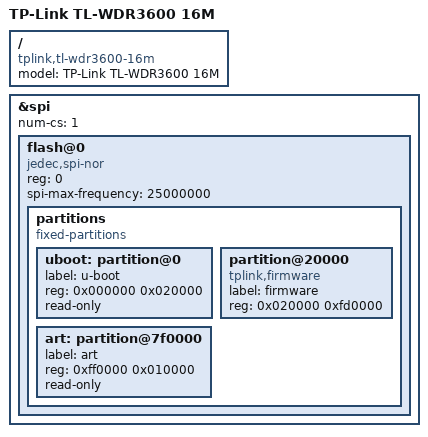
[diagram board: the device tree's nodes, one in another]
// SPDX-License-Identifier: GPL-2.0-or-later OR MIT
/dts-v1/;

#include "ar9344_tplink_tl-wdr4300.dtsi"

/ {
	model = "TP-Link TL-WDR3600 16M";
	compatible = "tplink,tl-wdr3600-16m", "qca,ar9344";
};

&spi {
       num-cs = <1>;

       status = "okay";

       flash@0 {
               compatible = "jedec,spi-nor";
               reg = <0>;
               spi-max-frequency = <25000000>;

               partitions {
                       compatible = "fixed-partitions";
                       #address-cells = <1>;
                       #size-cells = <1>;

                       uboot: partition@0 {
                               label = "u-boot";
                               reg = <0x000000 0x020000>;
                               read-only;
                       };

                       partition@20000 {
                               compatible = "tplink,firmware";
                               label = "firmware";
                               reg = <0x020000 0xfd0000>;
                       };

                       art: partition@7f0000 {
                               label = "art";
                               reg = <0xff0000 0x010000>;
                               read-only;
                       };
               };
       };
};
